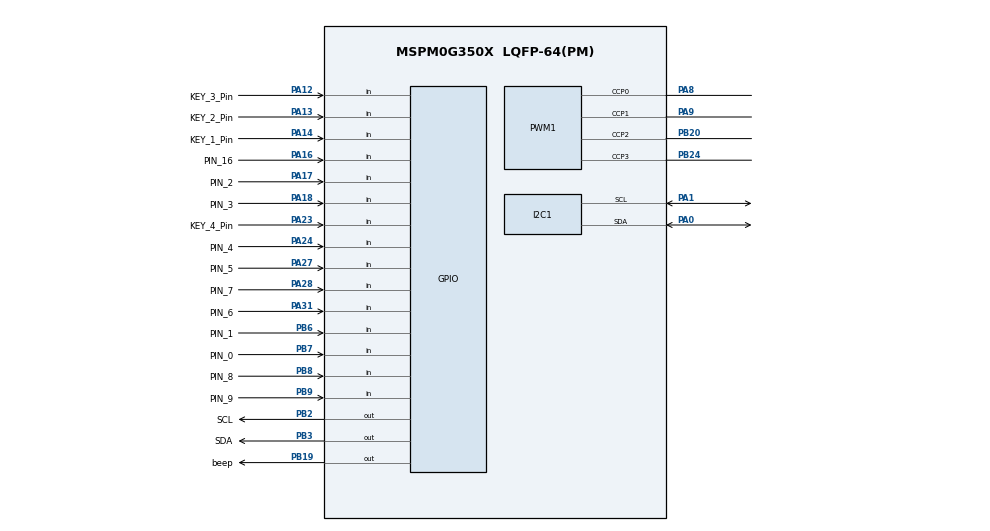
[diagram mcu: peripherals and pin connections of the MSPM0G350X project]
/**
 * @cliArgs --device "MSPM0G350X" --part "Default" --package "LQFP-64(PM)" --product "mspm0_sdk@2.04.00.06"
 * @versions {"tool":"1.22.0+3893"}
 */

/**
 * Import the modules used in this configuration.
 */
const GPIO   = scripting.addModule("/ti/driverlib/GPIO", {}, false);
const GPIO1  = GPIO.addInstance();
const GPIO2  = GPIO.addInstance();
const GPIO3  = GPIO.addInstance();
const GPIO4  = GPIO.addInstance();
const GPIO5  = GPIO.addInstance();
const GPIO6  = GPIO.addInstance();
const GPIO7  = GPIO.addInstance();
const GPIO8  = GPIO.addInstance();
const I2C    = scripting.addModule("/ti/driverlib/I2C", {}, false);
const I2C1   = I2C.addInstance();
const PWM    = scripting.addModule("/ti/driverlib/PWM", {}, false);
const PWM1   = PWM.addInstance();
const SYSCTL = scripting.addModule("/ti/driverlib/SYSCTL");
const TIMER  = scripting.addModule("/ti/driverlib/TIMER", {}, false);
const TIMER1 = TIMER.addInstance();
const UART   = scripting.addModule("/ti/driverlib/UART", {}, false);
const UART1  = UART.addInstance();

/**
 * Write custom configuration values to the imported modules.
 */
const divider7       = system.clockTree["PLL_PDIV"];
divider7.divideValue = 8;

const divider9       = system.clockTree["UDIV"];
divider9.divideValue = 2;

const gate7  = system.clockTree["MFCLKGATE"];
gate7.enable = true;

const multiplier2         = system.clockTree["PLL_QDIV"];
multiplier2.multiplyValue = 40;

const mux8       = system.clockTree["HSCLKMUX"];
mux8.inputSelect = "HSCLKMUX_SYSPLL0";

GPIO1.$name                               = "KEY";
GPIO1.associatedPins.create(4);
GPIO1.associatedPins[0].direction         = "INPUT";
GPIO1.associatedPins[0].internalResistor  = "PULL_UP";
GPIO1.associatedPins[0].interruptPriority = "0";
GPIO1.associatedPins[0].$name             = "KEY_1_Pin";
GPIO1.associatedPins[0].interruptEn       = true;
GPIO1.associatedPins[0].polarity          = "FALL";
GPIO1.associatedPins[0].pin.$assign       = "PA14";
GPIO1.associatedPins[1].direction         = "INPUT";
GPIO1.associatedPins[1].internalResistor  = "PULL_UP";
GPIO1.associatedPins[1].interruptPriority = "0";
GPIO1.associatedPins[1].$name             = "KEY_2_Pin";
GPIO1.associatedPins[1].interruptEn       = true;
GPIO1.associatedPins[1].polarity          = "FALL";
GPIO1.associatedPins[1].pin.$assign       = "PA13";
GPIO1.associatedPins[2].direction         = "INPUT";
GPIO1.associatedPins[2].internalResistor  = "PULL_UP";
GPIO1.associatedPins[2].interruptPriority = "0";
GPIO1.associatedPins[2].$name             = "KEY_3_Pin";
GPIO1.associatedPins[2].interruptEn       = true;
GPIO1.associatedPins[2].polarity          = "FALL";
GPIO1.associatedPins[2].pin.$assign       = "PA12";
GPIO1.associatedPins[3].$name             = "KEY_4_Pin";
GPIO1.associatedPins[3].direction         = "INPUT";
GPIO1.associatedPins[3].interruptEn       = true;
GPIO1.associatedPins[3].internalResistor  = "PULL_UP";
GPIO1.associatedPins[3].polarity          = "FALL";
GPIO1.associatedPins[3].interruptPriority = "0";
GPIO1.associatedPins[3].pin.$assign       = "PA23";

const Board = scripting.addModule("/ti/driverlib/Board", {}, false);

GPIO2.$name                          = "OLED";
GPIO2.associatedPins.create(2);
GPIO2.associatedPins[0].$name        = "SCL";
GPIO2.associatedPins[0].initialValue = "SET";
GPIO2.associatedPins[0].pin.$assign  = "PB2";
GPIO2.associatedPins[1].$name        = "SDA";
GPIO2.associatedPins[1].initialValue = "SET";
GPIO2.associatedPins[1].pin.$assign  = "PB3";

GPIO3.$name                              = "BEEP";
GPIO3.associatedPins[0].$name            = "beep";
GPIO3.associatedPins[0].internalResistor = "PULL_DOWN";
GPIO3.associatedPins[0].assignedPort     = "PORTB";
GPIO3.associatedPins[0].pin.$assign      = "PB19";

GPIO4.$name                               = "L1_Encoder_A";
GPIO4.port                                = "PORTA";
GPIO4.associatedPins[0].$name             = "PIN_15";
GPIO4.associatedPins[0].direction         = "INPUT";
GPIO4.associatedPins[0].interruptEn       = true;
GPIO4.associatedPins[0].polarity          = "RISE";
GPIO4.associatedPins[0].interruptPriority = "2";

GPIO5.$name                         = "L2_Encoder_B";
GPIO5.port                          = "PORTB";
GPIO5.associatedPins[0].$name       = "PIN_9";
GPIO5.associatedPins[0].direction   = "INPUT";
GPIO5.associatedPins[0].polarity    = "RISE";
GPIO5.associatedPins[0].pin.$assign = "PB9";

GPIO6.$name                               = "L2_Encoder_A";
GPIO6.port                                = "PORTB";
GPIO6.associatedPins[0].$name             = "PIN_8";
GPIO6.associatedPins[0].direction         = "INPUT";
GPIO6.associatedPins[0].interruptEn       = true;
GPIO6.associatedPins[0].polarity          = "RISE";
GPIO6.associatedPins[0].interruptPriority = "2";
GPIO6.associatedPins[0].pin.$assign       = "PB8";

GPIO7.$name                         = "L1_Encoder_B";
GPIO7.port                          = "PORTA";
GPIO7.associatedPins[0].$name       = "PIN_16";
GPIO7.associatedPins[0].direction   = "INPUT";
GPIO7.associatedPins[0].polarity    = "RISE";
GPIO7.associatedPins[0].pin.$assign = "PA16";

GPIO8.$name                              = "GPIO_gray";
GPIO8.associatedPins.create(8);
GPIO8.associatedPins[0].$name            = "PIN_0";
GPIO8.associatedPins[0].direction        = "INPUT";
GPIO8.associatedPins[0].internalResistor = "PULL_DOWN";
GPIO8.associatedPins[0].pin.$assign      = "PB7";
GPIO8.associatedPins[1].$name            = "PIN_1";
GPIO8.associatedPins[1].direction        = "INPUT";
GPIO8.associatedPins[1].internalResistor = "PULL_DOWN";
GPIO8.associatedPins[1].pin.$assign      = "PB6";
GPIO8.associatedPins[2].$name            = "PIN_2";
GPIO8.associatedPins[2].direction        = "INPUT";
GPIO8.associatedPins[2].internalResistor = "PULL_DOWN";
GPIO8.associatedPins[2].pin.$assign      = "PA17";
GPIO8.associatedPins[3].$name            = "PIN_3";
GPIO8.associatedPins[3].direction        = "INPUT";
GPIO8.associatedPins[3].internalResistor = "PULL_DOWN";
GPIO8.associatedPins[3].pin.$assign      = "PA18";
GPIO8.associatedPins[4].$name            = "PIN_4";
GPIO8.associatedPins[4].direction        = "INPUT";
GPIO8.associatedPins[4].internalResistor = "PULL_DOWN";
GPIO8.associatedPins[4].pin.$assign      = "PA24";
GPIO8.associatedPins[5].$name            = "PIN_5";
GPIO8.associatedPins[5].direction        = "INPUT";
GPIO8.associatedPins[5].internalResistor = "PULL_DOWN";
GPIO8.associatedPins[5].pin.$assign      = "PA27";
GPIO8.associatedPins[6].$name            = "PIN_6";
GPIO8.associatedPins[6].direction        = "INPUT";
GPIO8.associatedPins[6].internalResistor = "PULL_DOWN";
GPIO8.associatedPins[6].pin.$assign      = "PA31";
GPIO8.associatedPins[7].$name            = "PIN_7";
GPIO8.associatedPins[7].direction        = "INPUT";
GPIO8.associatedPins[7].internalResistor = "PULL_DOWN";
GPIO8.associatedPins[7].pin.$assign      = "PA28";

I2C1.$name                     = "I2C_0";
I2C1.basicEnableController     = true;
I2C1.peripheral.sdaPin.$assign = "PA0";
I2C1.peripheral.sclPin.$assign = "PA1";
I2C1.sdaPinConfig.$name        = "ti_driverlib_gpio_GPIOPinGeneric6";
I2C1.sclPinConfig.$name        = "ti_driverlib_gpio_GPIOPinGeneric7";

PWM1.$name                      = "PWM_0";
PWM1.clockPrescale              = 8;
PWM1.timerStartTimer            = true;
PWM1.ccIndex                    = [0,1,2,3];
PWM1.timerCount                 = 10000;
PWM1.pwmMode                    = "EDGE_ALIGN_UP";
PWM1.peripheral.ccp0Pin.$assign = "PA8";
PWM1.peripheral.ccp1Pin.$assign = "PA9";
PWM1.peripheral.ccp2Pin.$assign = "PB20";
PWM1.peripheral.ccp3Pin.$assign = "PB24";
PWM1.PWM_CHANNEL_0.$name        = "ti_driverlib_pwm_PWMTimerCC0";
PWM1.PWM_CHANNEL_1.$name        = "ti_driverlib_pwm_PWMTimerCC1";
PWM1.ccp0PinConfig.$name        = "ti_driverlib_gpio_GPIOPinGeneric0";
PWM1.ccp1PinConfig.$name        = "ti_driverlib_gpio_GPIOPinGeneric1";
PWM1.PWM_CHANNEL_2.$name        = "ti_driverlib_pwm_PWMTimerCC2";
PWM1.PWM_CHANNEL_3.$name        = "ti_driverlib_pwm_PWMTimerCC3";
PWM1.ccp2PinConfig.$name        = "ti_driverlib_gpio_GPIOPinGeneric2";
PWM1.ccp3PinConfig.$name        = "ti_driverlib_gpio_GPIOPinGeneric3";

SYSCTL.forceDefaultClkConfig = true;
SYSCTL.clockTreeEn           = true;

TIMER1.$name             = "TIMER_0";
TIMER1.timerMode         = "PERIODIC_UP";
TIMER1.timerPeriod       = "1 ms";
TIMER1.timerStartTimer   = true;
TIMER1.interrupts        = ["LOAD"];
TIMER1.interruptPriority = "0";
TIMER1.timerClkPrescale  = 80;

UART1.targetBaudRate                       = 115200;
UART1.$name                                = "Imu";
UART1.enabledDMARXTriggers                 = "DL_UART_DMA_INTERRUPT_RX";
UART1.interruptPriority                    = "0";
UART1.enableFIFO                           = true;
UART1.rxFifoThreshold                      = "DL_UART_RX_FIFO_LEVEL_ONE_ENTRY";
UART1.txFifoThreshold                      = "DL_UART_TX_FIFO_LEVEL_ONE_ENTRY";
UART1.enableDMARX                          = false;
UART1.enabledInterrupts                    = ["RX","TX"];
UART1.peripheral.$assign                   = "UART3";
UART1.txPinConfig.direction                = scripting.forceWrite("OUTPUT");
UART1.txPinConfig.hideOutputInversion      = scripting.forceWrite(false);
UART1.txPinConfig.onlyInternalResistor     = scripting.forceWrite(false);
UART1.txPinConfig.passedPeripheralType     = scripting.forceWrite("Digital");
UART1.txPinConfig.$name                    = "ti_driverlib_gpio_GPIOPinGeneric8";
UART1.rxPinConfig.hideOutputInversion      = scripting.forceWrite(false);
UART1.rxPinConfig.onlyInternalResistor     = scripting.forceWrite(false);
UART1.rxPinConfig.passedPeripheralType     = scripting.forceWrite("Digital");
UART1.rxPinConfig.$name                    = "ti_driverlib_gpio_GPIOPinGeneric9";
UART1.DMA_CHANNEL_RX.$name                 = "DMA_CH0";
UART1.DMA_CHANNEL_RX.configureTransferSize = true;
UART1.DMA_CHANNEL_RX.transferMode          = "FULL_CH_REPEAT_SINGLE";
UART1.DMA_CHANNEL_RX.srcLength             = "BYTE";
UART1.DMA_CHANNEL_RX.dstLength             = "BYTE";
UART1.DMA_CHANNEL_RX.addressMode           = "f2b";

/**
 * Pinmux solution for unlocked pins/peripherals. This ensures that minor changes to the automatic solver in a future
 * version of the tool will not impact the pinmux you originally saw.  These lines can be completely deleted in order to
 * re-solve from scratch.
 */
Board.peripheral.$suggestSolution                = "DEBUGSS";
Board.peripheral.swclkPin.$suggestSolution       = "PA20";
Board.peripheral.swdioPin.$suggestSolution       = "PA19";
GPIO4.associatedPins[0].pin.$suggestSolution     = "PA15";
I2C1.peripheral.$suggestSolution                 = "I2C0";
PWM1.peripheral.$suggestSolution                 = "TIMA0";
TIMER1.peripheral.$suggestSolution               = "TIMA1";
UART1.peripheral.rxPin.$suggestSolution          = "PA25";
UART1.peripheral.txPin.$suggestSolution          = "PA26";
UART1.DMA_CHANNEL_RX.peripheral.$suggestSolution = "DMA_CH0";
